# ESP32-S31 register map
Vendor: ESPRESSIF SYSTEMS (SHANGHAI) CO., LTD.; Series: ESP32 S-Series; File version: 1
CPU: RV32IMAFC r0p0, little endian, no MPU, FPU, 0 interrupt priority bits
Address unit: 32 bits
Registers are 32-bit, read-write, reset 0x0 unless marked. A register's access mark holds for its fields unless they carry their own. Offsets are from the block's base; [hi:lo] are bit positions; {n}, {i} and the like mark numbered series; 'fields as' and 'values as' point back to an identical list.

## MODEM_LPCON
Base 0x2010F000
0x00 TEST_CONF
  [0] CLK_EN
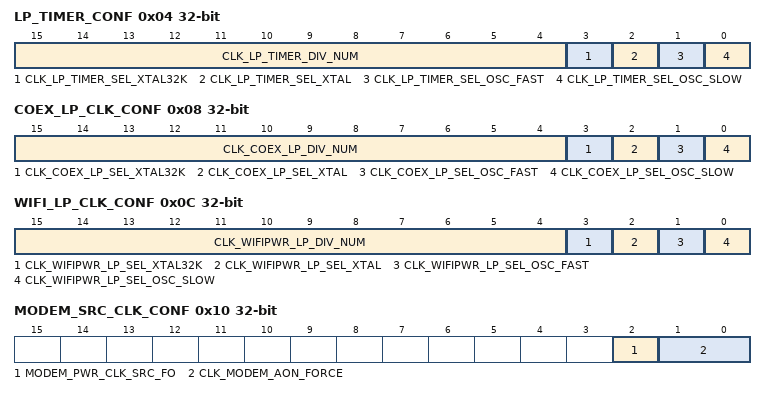
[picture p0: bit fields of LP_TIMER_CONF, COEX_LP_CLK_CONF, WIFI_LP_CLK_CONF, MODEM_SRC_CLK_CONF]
0x04 LP_TIMER_CONF
  [15:4] CLK_LP_TIMER_DIV_NUM, [3] CLK_LP_TIMER_SEL_XTAL32K, [2] CLK_LP_TIMER_SEL_XTAL, [1] CLK_LP_TIMER_SEL_OSC_FAST, [0] CLK_LP_TIMER_SEL_OSC_SLOW
0x08 COEX_LP_CLK_CONF
  [15:4] CLK_COEX_LP_DIV_NUM, [3] CLK_COEX_LP_SEL_XTAL32K, [2] CLK_COEX_LP_SEL_XTAL, [1] CLK_COEX_LP_SEL_OSC_FAST, [0] CLK_COEX_LP_SEL_OSC_SLOW
0x0C WIFI_LP_CLK_CONF
  [15:4] CLK_WIFIPWR_LP_DIV_NUM, [3] CLK_WIFIPWR_LP_SEL_XTAL32K, [2] CLK_WIFIPWR_LP_SEL_XTAL, [1] CLK_WIFIPWR_LP_SEL_OSC_FAST, [0] CLK_WIFIPWR_LP_SEL_OSC_SLOW
0x10 MODEM_SRC_CLK_CONF
  [2] MODEM_PWR_CLK_SRC_FO, [1:0] CLK_MODEM_AON_FORCE
0x14 MODEM_32K_CLK_CONF
  [1:0] CLK_MODEM_32K_SEL
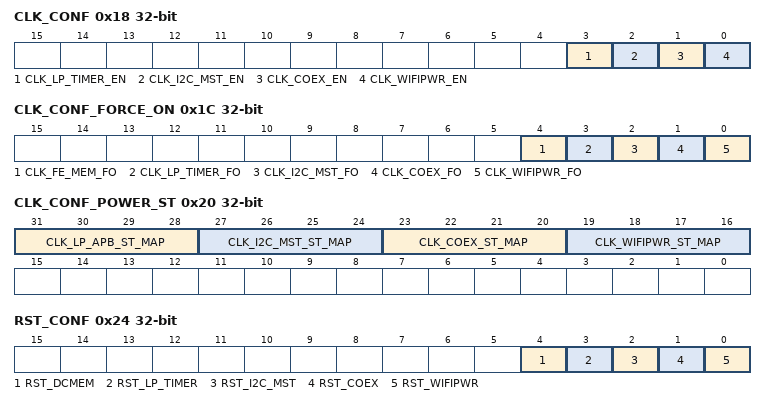
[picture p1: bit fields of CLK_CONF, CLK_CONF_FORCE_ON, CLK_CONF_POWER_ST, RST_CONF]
0x18 CLK_CONF
  [3] CLK_LP_TIMER_EN, [2] CLK_I2C_MST_EN, [1] CLK_COEX_EN, [0] CLK_WIFIPWR_EN
0x1C CLK_CONF_FORCE_ON
  [4] CLK_FE_MEM_FO, [3] CLK_LP_TIMER_FO, [2] CLK_I2C_MST_FO, [1] CLK_COEX_FO, [0] CLK_WIFIPWR_FO
0x20 CLK_CONF_POWER_ST
  [31:28] CLK_LP_APB_ST_MAP, [27:24] CLK_I2C_MST_ST_MAP, [23:20] CLK_COEX_ST_MAP, [19:16] CLK_WIFIPWR_ST_MAP
0x24 RST_CONF
  [4] RST_DCMEM, [3] RST_LP_TIMER, [2] RST_I2C_MST, [1] RST_COEX, [0] RST_WIFIPWR
0x28 TICK_CONF reset 0x27
  [5:0] MODEM_PWR_TICK_TARGET
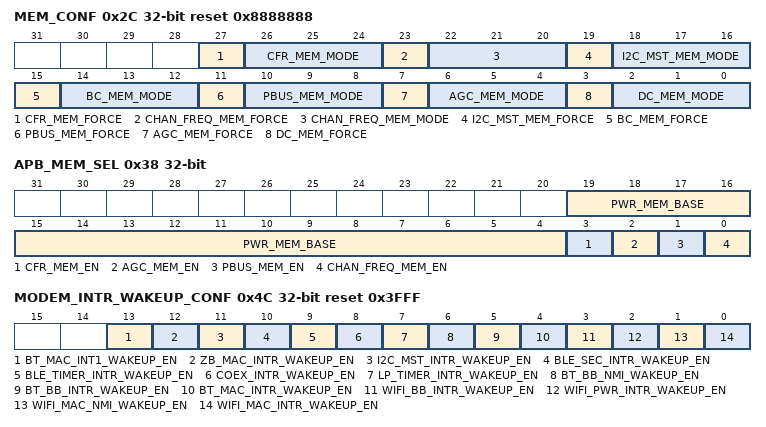
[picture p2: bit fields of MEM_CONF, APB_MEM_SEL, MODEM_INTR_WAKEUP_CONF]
0x2C MEM_CONF reset 0x8888888
  [27] CFR_MEM_FORCE, [26:24] CFR_MEM_MODE, [23] CHAN_FREQ_MEM_FORCE, [22:20] CHAN_FREQ_MEM_MODE, [19] I2C_MST_MEM_FORCE, [18:16] I2C_MST_MEM_MODE, [15] BC_MEM_FORCE, [14:12] BC_MEM_MODE, [11] PBUS_MEM_FORCE, [10:8] PBUS_MEM_MODE, [7] AGC_MEM_FORCE, [6:4] AGC_MEM_MODE, [3] DC_MEM_FORCE, [2:0] DC_MEM_MODE
0x30 MEM_RF1_AUX_CTRL reset 0x2070
  [31:0] MODEM_PWR_RF1_AUX_CTRL
0x34 MEM_RF2_AUX_CTRL
  [31:0] MODEM_PWR_RF2_AUX_CTRL
0x38 APB_MEM_SEL
  [19:4] PWR_MEM_BASE, [3] CFR_MEM_EN, [2] AGC_MEM_EN, [1] PBUS_MEM_EN, [0] CHAN_FREQ_MEM_EN
{0x3C+4i} DCMEM_VALID_{i} (i=0..3)
0x4C MODEM_INTR_WAKEUP_CONF reset 0x3FFF
  [13] BT_MAC_INT1_WAKEUP_EN, [12] ZB_MAC_INTR_WAKEUP_EN, [11] I2C_MST_INTR_WAKEUP_EN, [10] BLE_SEC_INTR_WAKEUP_EN, [9] BLE_TIMER_INTR_WAKEUP_EN, [8] COEX_INTR_WAKEUP_EN, [7] LP_TIMER_INTR_WAKEUP_EN, [6] BT_BB_NMI_WAKEUP_EN, [5] BT_BB_INTR_WAKEUP_EN, [4] BT_MAC_INTR_WAKEUP_EN, [3] WIFI_BB_INTR_WAKEUP_EN, [2] WIFI_PWR_INTR_WAKEUP_EN, [1] WIFI_MAC_NMI_WAKEUP_EN, [0] WIFI_MAC_INTR_WAKEUP_EN
0x50 MODEM_INTR_STATUS
  [13:0] MODEM_INTR_VECTOR
0x54 MEM_CONF2 reset 0x4
  [3:0] PWR_MEM_MODE_SEL
0x58 DATE reset 0x2508150
  [27:0] DATE

## I2C_ANA_MST — I2C_ANA_MST Peripheral
Base 0x2010F800
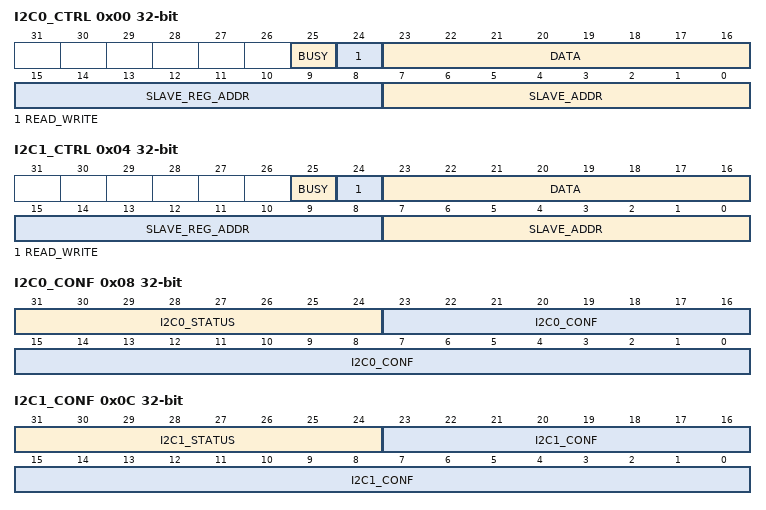
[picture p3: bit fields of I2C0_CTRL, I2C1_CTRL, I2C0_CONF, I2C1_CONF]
0x00 I2C0_CTRL
  [25] BUSY, [24] READ_WRITE, [23:16] DATA, [15:8] SLAVE_REG_ADDR, [7:0] SLAVE_ADDR
0x04 I2C1_CTRL
  fields as I2C0_CTRL
0x08 I2C0_CONF
  [31:24] I2C0_STATUS, [23:0] I2C0_CONF
0x0C I2C1_CONF
  [31:24] I2C1_STATUS, [23:0] I2C1_CONF
0x10 I2C_BURST_CONF
  [31:0] I2C_MST_BURST_CTRL
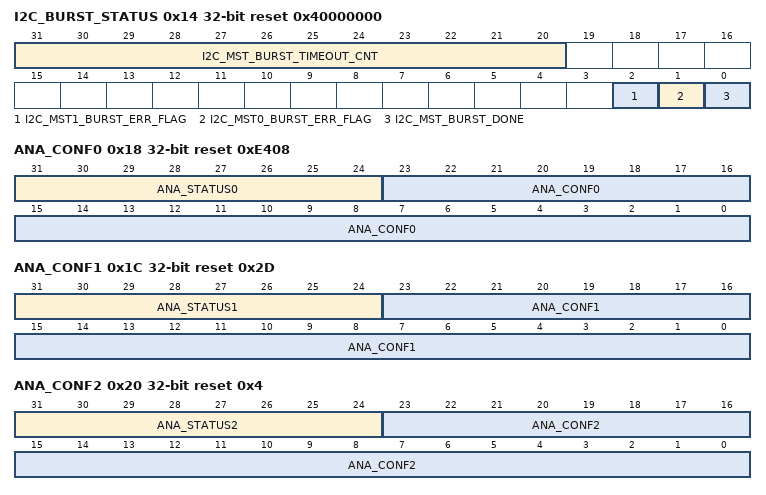
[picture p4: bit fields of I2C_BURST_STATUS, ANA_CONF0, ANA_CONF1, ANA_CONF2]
0x14 I2C_BURST_STATUS reset 0x40000000
  [31:20] I2C_MST_BURST_TIMEOUT_CNT, [2] I2C_MST1_BURST_ERR_FLAG, [1] I2C_MST0_BURST_ERR_FLAG, [0] I2C_MST_BURST_DONE
0x18 ANA_CONF0 reset 0xE408
  [31:24] ANA_STATUS0, [23:0] ANA_CONF0
0x1C ANA_CONF1 reset 0x2D
  [31:24] ANA_STATUS1, [23:0] ANA_CONF1
0x20 ANA_CONF2 reset 0x4
  [31:24] ANA_STATUS2, [23:0] ANA_CONF2
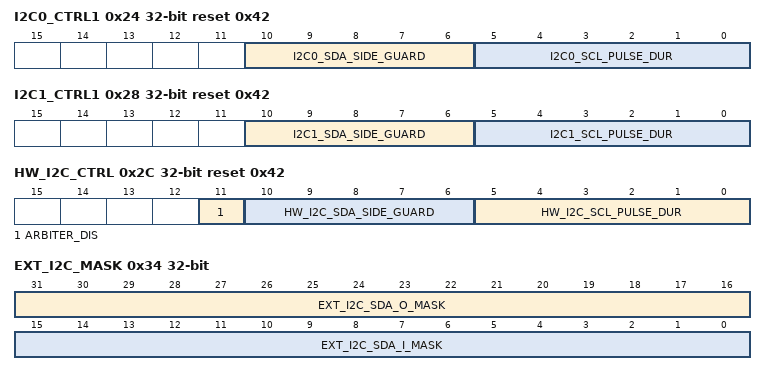
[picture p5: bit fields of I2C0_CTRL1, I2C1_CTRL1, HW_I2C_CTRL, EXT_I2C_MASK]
0x24 I2C0_CTRL1 reset 0x42
  [10:6] I2C0_SDA_SIDE_GUARD, [5:0] I2C0_SCL_PULSE_DUR
0x28 I2C1_CTRL1 reset 0x42
  [10:6] I2C1_SDA_SIDE_GUARD, [5:0] I2C1_SCL_PULSE_DUR
0x2C HW_I2C_CTRL reset 0x42
  [11] ARBITER_DIS, [10:6] HW_I2C_SDA_SIDE_GUARD, [5:0] HW_I2C_SCL_PULSE_DUR
0x30 I2C_MST_NOUSE
0x34 EXT_I2C_MASK
  [31:16] EXT_I2C_SDA_O_MASK, [15:0] EXT_I2C_SDA_I_MASK
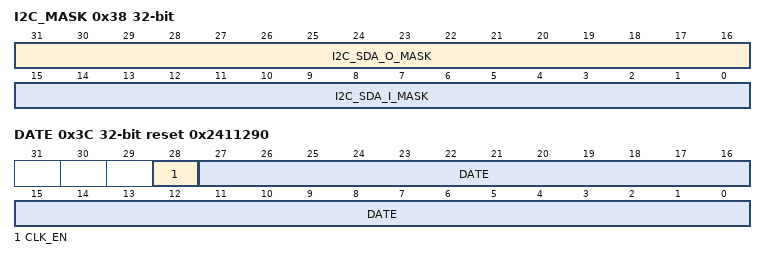
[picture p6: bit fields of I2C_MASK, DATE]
0x38 I2C_MASK
  [31:16] I2C_SDA_O_MASK, [15:0] I2C_SDA_I_MASK
0x3C DATE reset 0x2411290
  [28] CLK_EN, [27:0] DATE
